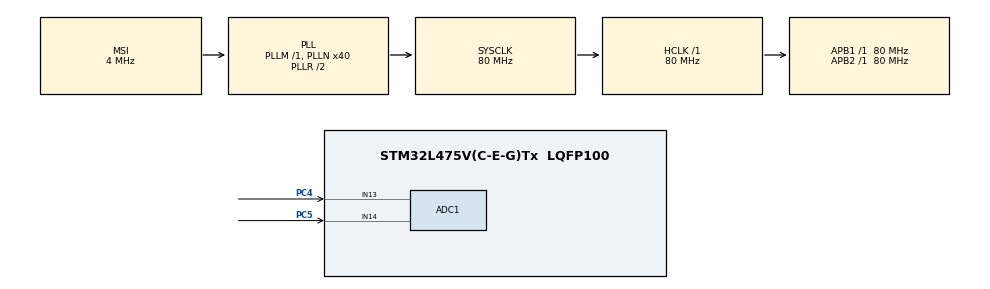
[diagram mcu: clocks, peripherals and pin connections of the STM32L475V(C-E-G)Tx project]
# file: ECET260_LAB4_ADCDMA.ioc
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ADC1.Channel-2\#ChannelRegularConversion=ADC_CHANNEL_14
ADC1.Channel-3\#ChannelRegularConversion=ADC_CHANNEL_13
ADC1.ContinuousConvMode=ENABLE
ADC1.DMAContinuousRequests=ENABLE
ADC1.EnableRegularConversion=ENABLE
ADC1.NbrOfConversion=2
ADC1.NbrOfConversionFlag=1
ADC1.OffsetNumber-2\#ChannelRegularConversion=ADC_OFFSET_NONE
ADC1.OffsetNumber-3\#ChannelRegularConversion=ADC_OFFSET_NONE
ADC1.Rank-2\#ChannelRegularConversion=1
ADC1.Rank-3\#ChannelRegularConversion=2
ADC1.SamplingTime-2\#ChannelRegularConversion=ADC_SAMPLETIME_47CYCLES_5
ADC1.SamplingTime-3\#ChannelRegularConversion=ADC_SAMPLETIME_47CYCLES_5
ADC1.master=1
Dma.ADC1.0.Direction=DMA_PERIPH_TO_MEMORY
Dma.ADC1.0.Instance=DMA1_Channel1
Dma.ADC1.0.MemDataAlignment=DMA_MDATAALIGN_WORD
Dma.ADC1.0.MemInc=DMA_MINC_ENABLE
Dma.ADC1.0.Mode=DMA_CIRCULAR
Dma.ADC1.0.PeriphDataAlignment=DMA_PDATAALIGN_HALFWORD
Dma.ADC1.0.PeriphInc=DMA_PINC_DISABLE
Dma.ADC1.0.Priority=DMA_PRIORITY_LOW
Dma.Request0=ADC1
Mcu.Family=STM32L4
Mcu.Name=STM32L475V(C-E-G)Tx
Mcu.Package=LQFP100
NVIC.DMA1_Channel1_IRQn=true\:0\:0\:false\:false\:true\:false\:true
NVIC.PriorityGroup=NVIC_PRIORITYGROUP_4
PC4.Signal=ADCx_IN13
PC5.Signal=ADCx_IN14
ProjectManager.HeapSize=0x200
ProjectManager.StackSize=0x400
ProjectManager.TargetToolchain=TrueSTUDIO
RCC.ADCFreq_Value=32000000
RCC.AHBFreq_Value=80000000
RCC.APB1Freq_Value=80000000
RCC.APB1TimFreq_Value=80000000
RCC.APB2Freq_Value=80000000
RCC.APB2TimFreq_Value=80000000
RCC.CortexFreq_Value=80000000
RCC.HCLKFreq_Value=80000000
RCC.HSE_VALUE=8000000
RCC.HSI_VALUE=16000000
RCC.LSE_VALUE=32768
RCC.MSI_VALUE=4000000
RCC.PLLN=40
RCC.PLLSAI1N=16
RCC.SYSCLKFreq_VALUE=80000000
RCC.SYSCLKSource=RCC_SYSCLKSOURCE_PLLCLK
RCC.USBFreq_Value=32000000
RCC.VCOOutputFreq_Value=160000000
SH.ADCx_IN13.0=ADC1_IN13,IN13-Single-Ended
SH.ADCx_IN14.0=ADC1_IN14,IN14-Single-Ended
board=custom

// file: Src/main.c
/* USER CODE BEGIN Header */
/**
  ******************************************************************************
  * @file           : main.c
  * @brief          : Main program body
  ******************************************************************************
  * @attention
  *
  * <h2><center>&copy; Copyright (c) 2019 STMicroelectronics.
  * All rights reserved.</center></h2>
  *
  * This software component is licensed by ST under BSD 3-Clause license,
  * the "License"; You may not use this file except in compliance with the
  * License. You may obtain a copy of the License at:
  *                        opensource.org/licenses/BSD-3-Clause
  *
  ******************************************************************************
  */
/* USER CODE END Header */

#include "main.h"
#include <stdint.h>
#include <stdio.h>

ADC_HandleTypeDef hadc1;
DMA_HandleTypeDef hdma_adc1;

/* USER CODE BEGIN PV */
uint32_t LMvalues[200];
uint32_t LM35Values;
uint32_t LM34Values;
float LM35temp = 0.0;
float LM34temp = 0.0;
/* USER CODE END PV */

void SystemClock_Config(void);
static void MX_GPIO_Init(void);
static void MX_DMA_Init(void);
static void MX_ADC1_Init(void);

int main(void)
{

  /* MCU Configuration--------------------------------------------------------*/

  /* Reset of all peripherals, Initializes the Flash interface and the Systick. */
  HAL_Init();

  /* Configure the system clock */
  SystemClock_Config();

  /* Initialize all configured peripherals */
  MX_GPIO_Init();
  MX_DMA_Init();
  MX_ADC1_Init();
  /* USER CODE BEGIN 2 */
  HAL_ADC_Start_DMA(&hadc1,LMvalues,200);
  /* USER CODE END 2 */

  /* Infinite loop */
  /* USER CODE BEGIN WHILE */
  while (1)
  {
	  int i;
	  for(i=0; i<199 ; i+=2)
	  {
		LM35Values = LM35Values + LMvalues[i];

	  }

	  for(i=1; i<200 ; i+=2)
	 	  {
	 		LM34Values = LM34Values + LMvalues[i];

	 	  }
      LM35Values = LM35Values/100;
      LM34Values = LM34Values/100;
      LM35temp = (LM35Values/4095.0)*329.8;
      LM34temp = (LM34Values/4095.0)*329.8;
      printf("LM35temp: %0.2fC   LM34temp: %0.2fF\n", LM35temp, LM34temp);
      HAL_Delay(500);

  }
  /* USER CODE END 3 */
}

void SystemClock_Config(void)
{
  RCC_OscInitTypeDef RCC_OscInitStruct = {0};
  RCC_ClkInitTypeDef RCC_ClkInitStruct = {0};
  RCC_PeriphCLKInitTypeDef PeriphClkInit = {0};

  /** Initializes the CPU, AHB and APB busses clocks
  */
  RCC_OscInitStruct.OscillatorType = RCC_OSCILLATORTYPE_MSI;
  RCC_OscInitStruct.MSIState = RCC_MSI_ON;
  RCC_OscInitStruct.MSICalibrationValue = 0;
  RCC_OscInitStruct.MSIClockRange = RCC_MSIRANGE_6;
  RCC_OscInitStruct.PLL.PLLState = RCC_PLL_ON;
  RCC_OscInitStruct.PLL.PLLSource = RCC_PLLSOURCE_MSI;
  RCC_OscInitStruct.PLL.PLLM = 1;
  RCC_OscInitStruct.PLL.PLLN = 40;
  RCC_OscInitStruct.PLL.PLLP = RCC_PLLP_DIV7;
  RCC_OscInitStruct.PLL.PLLQ = RCC_PLLQ_DIV2;
  RCC_OscInitStruct.PLL.PLLR = RCC_PLLR_DIV2;
  if (HAL_RCC_OscConfig(&RCC_OscInitStruct) != HAL_OK)
  {
    Error_Handler();
  }
  /** Initializes the CPU, AHB and APB busses clocks
  */
  RCC_ClkInitStruct.ClockType = RCC_CLOCKTYPE_HCLK|RCC_CLOCKTYPE_SYSCLK
                              |RCC_CLOCKTYPE_PCLK1|RCC_CLOCKTYPE_PCLK2;
  RCC_ClkInitStruct.SYSCLKSource = RCC_SYSCLKSOURCE_PLLCLK;
  RCC_ClkInitStruct.AHBCLKDivider = RCC_SYSCLK_DIV1;
  RCC_ClkInitStruct.APB1CLKDivider = RCC_HCLK_DIV1;
  RCC_ClkInitStruct.APB2CLKDivider = RCC_HCLK_DIV1;

  if (HAL_RCC_ClockConfig(&RCC_ClkInitStruct, FLASH_LATENCY_4) != HAL_OK)
  {
    Error_Handler();
  }
  PeriphClkInit.PeriphClockSelection = RCC_PERIPHCLK_ADC;
  PeriphClkInit.AdcClockSelection = RCC_ADCCLKSOURCE_PLLSAI1;
  PeriphClkInit.PLLSAI1.PLLSAI1Source = RCC_PLLSOURCE_MSI;
  PeriphClkInit.PLLSAI1.PLLSAI1M = 1;
  PeriphClkInit.PLLSAI1.PLLSAI1N = 16;
  PeriphClkInit.PLLSAI1.PLLSAI1P = RCC_PLLP_DIV7;
  PeriphClkInit.PLLSAI1.PLLSAI1Q = RCC_PLLQ_DIV2;
  PeriphClkInit.PLLSAI1.PLLSAI1R = RCC_PLLR_DIV2;
  PeriphClkInit.PLLSAI1.PLLSAI1ClockOut = RCC_PLLSAI1_ADC1CLK;
  if (HAL_RCCEx_PeriphCLKConfig(&PeriphClkInit) != HAL_OK)
  {
    Error_Handler();
  }
  /** Configure the main internal regulator output voltage
  */
  if (HAL_PWREx_ControlVoltageScaling(PWR_REGULATOR_VOLTAGE_SCALE1) != HAL_OK)
  {
    Error_Handler();
  }
}

static void MX_ADC1_Init(void)
{

  ADC_MultiModeTypeDef multimode = {0};
  ADC_ChannelConfTypeDef sConfig = {0};

  /** Common config
  */
  hadc1.Instance = ADC1;
  hadc1.Init.ClockPrescaler = ADC_CLOCK_ASYNC_DIV1;
  hadc1.Init.Resolution = ADC_RESOLUTION_12B;
  hadc1.Init.DataAlign = ADC_DATAALIGN_RIGHT;
  hadc1.Init.ScanConvMode = ADC_SCAN_ENABLE;
  hadc1.Init.EOCSelection = ADC_EOC_SINGLE_CONV;
  hadc1.Init.LowPowerAutoWait = DISABLE;
  hadc1.Init.ContinuousConvMode = ENABLE;
  hadc1.Init.NbrOfConversion = 2;
  hadc1.Init.DiscontinuousConvMode = DISABLE;
  hadc1.Init.ExternalTrigConv = ADC_SOFTWARE_START;
  hadc1.Init.ExternalTrigConvEdge = ADC_EXTERNALTRIGCONVEDGE_NONE;
  hadc1.Init.DMAContinuousRequests = ENABLE;
  hadc1.Init.Overrun = ADC_OVR_DATA_PRESERVED;
  hadc1.Init.OversamplingMode = DISABLE;
  if (HAL_ADC_Init(&hadc1) != HAL_OK)
  {
    Error_Handler();
  }
  /** Configure the ADC multi-mode
  */
  multimode.Mode = ADC_MODE_INDEPENDENT;
  if (HAL_ADCEx_MultiModeConfigChannel(&hadc1, &multimode) != HAL_OK)
  {
    Error_Handler();
  }
  /** Configure Regular Channel
  */
  sConfig.Channel = ADC_CHANNEL_14;
  sConfig.Rank = ADC_REGULAR_RANK_1;
  sConfig.SamplingTime = ADC_SAMPLETIME_47CYCLES_5;
  sConfig.SingleDiff = ADC_SINGLE_ENDED;
  sConfig.OffsetNumber = ADC_OFFSET_NONE;
  sConfig.Offset = 0;
  if (HAL_ADC_ConfigChannel(&hadc1, &sConfig) != HAL_OK)
  {
    Error_Handler();
  }
  /** Configure Regular Channel
  */
  sConfig.Channel = ADC_CHANNEL_13;
  sConfig.Rank = ADC_REGULAR_RANK_2;
  if (HAL_ADC_ConfigChannel(&hadc1, &sConfig) != HAL_OK)
  {
    Error_Handler();
  }

}

static void MX_DMA_Init(void)
{

  /* DMA controller clock enable */
  __HAL_RCC_DMA1_CLK_ENABLE();

  /* DMA interrupt init */
  /* DMA1_Channel1_IRQn interrupt configuration */
  HAL_NVIC_SetPriority(DMA1_Channel1_IRQn, 0, 0);
  HAL_NVIC_EnableIRQ(DMA1_Channel1_IRQn);

}

static void MX_GPIO_Init(void)
{

  /* GPIO Ports Clock Enable */
  __HAL_RCC_GPIOC_CLK_ENABLE();

}

/* USER CODE BEGIN 4 */
int __io_putchar(int ch)
{
	ITM_SendChar(ch);
	return 0;
}
/* USER CODE END 4 */

void Error_Handler(void)
{
}

/************************ (C) COPYRIGHT STMicroelectronics *****END OF FILE****/
